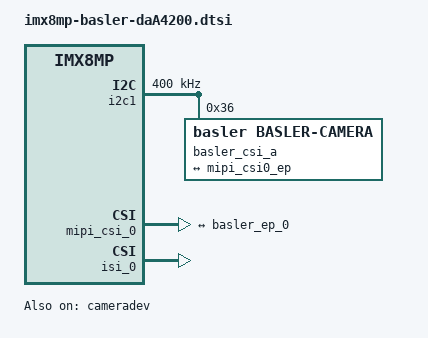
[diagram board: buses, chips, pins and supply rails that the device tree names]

&i2c1 {
	clock-frequency = <400000>;
	pinctrl-names = "default";
	pinctrl-0 = <&pinctrl_i2c1>;
	status = "okay";

	basler_csi_a: basler_camera_vvcam@36 {
		compatible = "basler,basler-camera";
		reg = <0x36>;
		csi_id = <0x00>;
		status = "okay";

		port {
			basler_ep_0: endpoint {
				remote-endpoint = <&mipi_csi0_ep>;
				data-lanes = <1 2 3 4>;
				clock-lanes = <0>;
				//link-frequenc = /bits/ 64 <594000000>;

				link-frequencies = /bits/ 64 <500000000>;
				max-lane-frequency = /bits/ 64 <750000000>;
				max-pixel-frequency = /bits/ 64 <750000000>;
				max-data-rate = /bits/ 64 <0>;

			};
		};
	};
};

&mipi_csi_0 {
	#address-cells = <1>;
	#size-cells = <0>;
	status = "okay";
	port@0 {
		reg = <0>;
		mipi_csi0_ep: endpoint {
			remote-endpoint = <&basler_ep_0>;
			data-lanes = <4>;
			csis-hs-settle = <16>;
		};
	};
};

&isi_0 {
	status = "okay";
};

&cameradev {
	status = "okay";
};
